# TMS320F280049 register map
Vendor: Texas Instruments; Series: C2000 F28004x; File version: 0.2.0-generated
Registers are 16-bit, read-write, reset 0x0 unless marked. A register's access mark holds for its fields unless they carry their own. Offsets are from the block's base; [hi:lo] are bit positions; {n}, {i} and the like mark numbered series; 'fields as' and 'values as' point back to an identical list.

## GPIOCTRLREGS — GPIO CTRL Registers
Base 0x0000F800
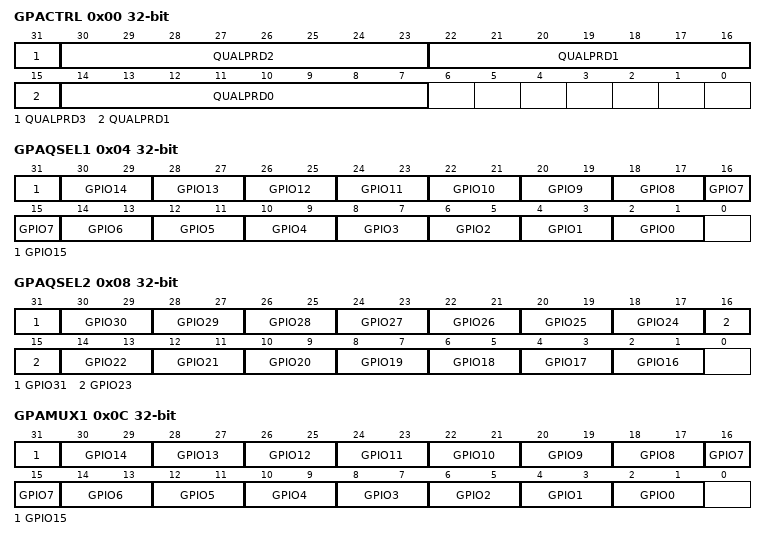
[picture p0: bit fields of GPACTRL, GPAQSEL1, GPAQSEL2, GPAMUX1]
0x00 GPACTRL 32-bit — GPIO A Qualification Sampling Period (GPIO0 to GPIO31)
  [31] QUALPRD3 — Qualification sampling period for GPIO24 to GPIO31
  [30:23] QUALPRD2 — Qualification sampling period for GPIO16 to GPIO23
  [22:15] QUALPRD1 — Qualification sampling period for GPIO8 to GPIO15
  [14:7] QUALPRD0 — Qualification sampling period for GPIO0 to GPIO7
0x04 GPAQSEL1 32-bit — GPIO A Qualification Type (GPIO0 to GPIO15)
  [31] GPIO15 — Select input qualification type for GPIO15
  [2n+2:2n+1] GPIO{n} (n=0..14) — Select input qualification type for GPIO{n}
0x08 GPAQSEL2 32-bit — GPIO A Qualification Type (GPIO16 to GPIO31)
  [31] GPIO31 — Select input qualification type for GPIO31
  [2n-30:2n-31] GPIO{n} (n=16..30) — Select input qualification type for GPIO{n}
0x0C GPAMUX1 32-bit — GPIO A Peripheral Mux (GPIO0 to GPIO15)
  [31] GPIO15 — Defines pin-muxing selection for GPIO15
  [2n+2:2n+1] GPIO{n} (n=0..14) — Defines pin-muxing selection for GPIO{n}
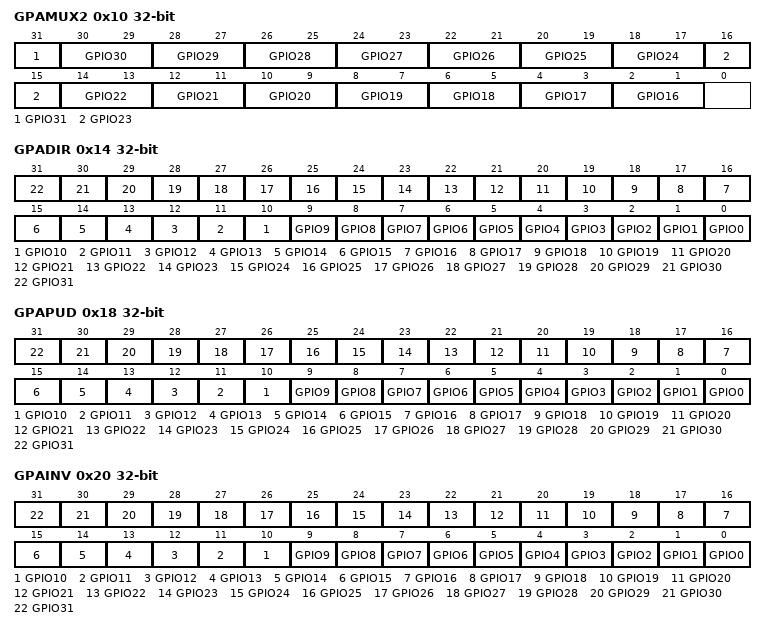
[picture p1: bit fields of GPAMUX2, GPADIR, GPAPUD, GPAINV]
0x10 GPAMUX2 32-bit — GPIO A Peripheral Mux (GPIO16 to GPIO31)
  [31] GPIO31 — Defines pin-muxing selection for GPIO31
  [2n-30:2n-31] GPIO{n} (n=16..30) — Defines pin-muxing selection for GPIO{n}
0x14 GPADIR 32-bit — GPIO A Direction (GPIO0 to GPIO31)
  [n] GPIO{n} (n=0..31) — Defines direction for this pin in GPIO mode
0x18 GPAPUD 32-bit — GPIO A Pull-Up Disable (GPIO0 to GPIO31)
  [n] GPIO{n} (n=0..31) — Pull-Up Disable control for this pin
0x20 GPAINV 32-bit — GPIO A Input Inversion (GPIO0 to GPIO31)
  [n] GPIO{n} (n=0..31) — Input inversion control for this pin
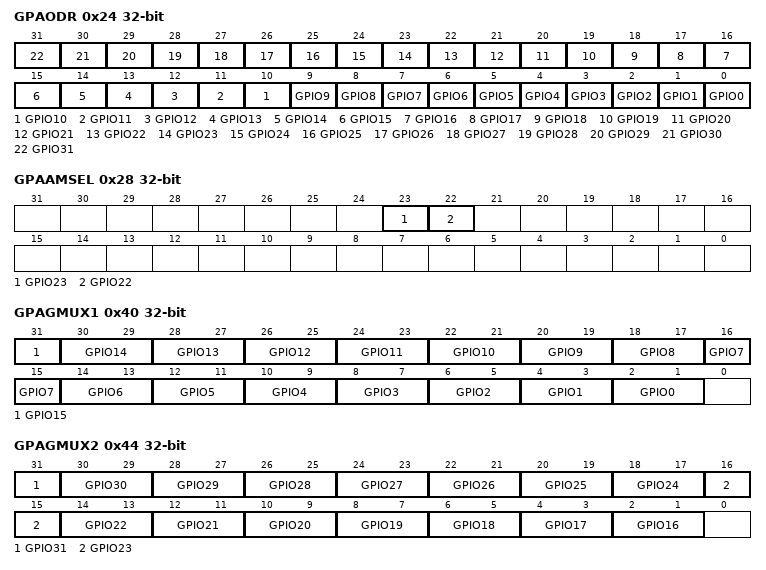
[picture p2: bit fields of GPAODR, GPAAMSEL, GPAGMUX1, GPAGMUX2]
0x24 GPAODR 32-bit — GPIO A Open Drain Output Mode (GPIO0 to GPIO31)
  [n] GPIO{n} (n=0..31) — Output Open-Drain control for this pin
0x28 GPAAMSEL 32-bit — GPIO A Analog Mode Select (GPIO0 to GPIO31)
  [23] GPIO23 — Analog Mode select for this pin
  [22] GPIO22 — Analog Mode select for this pin
0x40 GPAGMUX1 32-bit — GPIO A Peripheral Group Mux (GPIO0 to GPIO15)
  fields as GPAMUX1
0x44 GPAGMUX2 32-bit — GPIO A Peripheral Group Mux (GPIO16 to GPIO31)
  fields as GPAMUX2
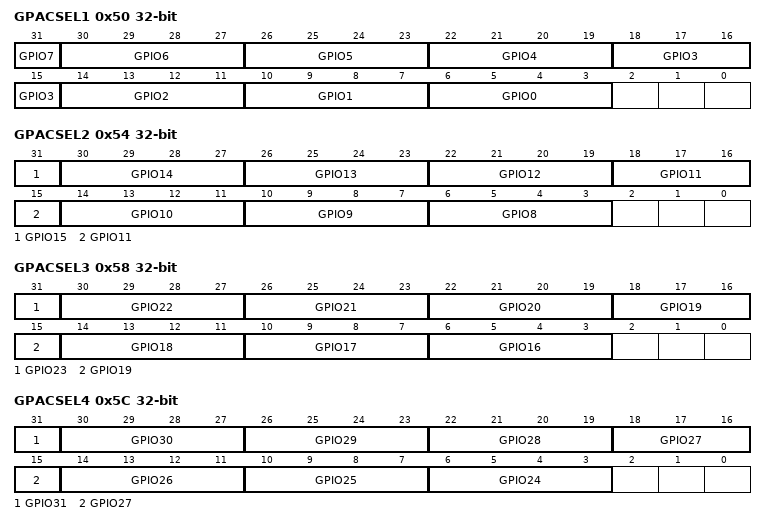
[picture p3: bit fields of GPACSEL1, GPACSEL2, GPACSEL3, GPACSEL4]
0x50 GPACSEL1 32-bit — GPIO A Master Core Select (GPIO0 to GPIO7)
  [31] GPIO7 — GPIO7 Master CPU Select
  [4n+6:4n+3] GPIO{n} (n=0..6) — GPIO{n} Master CPU Select
0x54 GPACSEL2 32-bit — GPIO A Master Core Select (GPIO8 to GPIO15)
  [31] GPIO15 — GPIO15 Master CPU Select
  [4n-26:4n-29] GPIO{n} (n=8..14) — GPIO{n} Master CPU Select
0x58 GPACSEL3 32-bit — GPIO A Master Core Select (GPIO16 to GPIO23)
  [31] GPIO23 — GPIO23 Master CPU Select
  [4n-58:4n-61] GPIO{n} (n=16..22) — GPIO{n} Master CPU Select
0x5C GPACSEL4 32-bit — GPIO A Master Core Select (GPIO24 to GPIO31)
  [31] GPIO31 — GPIO31 Master CPU Select
  [4n-90:4n-93] GPIO{n} (n=24..30) — GPIO{n} Master CPU Select
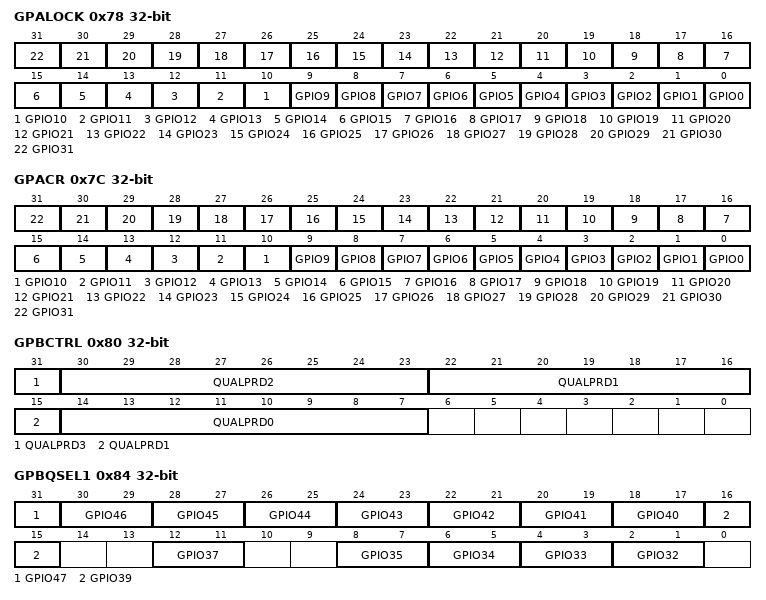
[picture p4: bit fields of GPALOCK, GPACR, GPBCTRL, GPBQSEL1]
0x78 GPALOCK 32-bit — GPIO A Lock Register (GPIO0 to GPIO31)
  [n] GPIO{n} (n=0..31) — Configuration Lock bit for this pin
0x7C GPACR 32-bit — GPIO A Lock Commit Register (GPIO0 to GPIO31)
  [n] GPIO{n} (n=0..31) — Configuration lock commit bit for this pin
0x80 GPBCTRL 32-bit — GPIO B Qualification Sampling Period (GPIO32 to GPIO63)
  [31] QUALPRD3 — Qualification sampling period for GPIO56 to GPIO63
  [30:23] QUALPRD2 — Qualification sampling period for GPIO48 to GPIO55
  [22:15] QUALPRD1 — Qualification sampling period for GPIO40 to GPIO47
  [14:7] QUALPRD0 — Qualification sampling period for GPIO32 to GPIO39
0x84 GPBQSEL1 32-bit — GPIO B Qualification Type (GPIO32 to GPIO47)
  [31] GPIO47 — Select input qualification type for GPIO47
  [2n-62:2n-63] GPIO{n} (n=39..46) — Select input qualification type for GPIO{n}
  [12:11] GPIO37 — Select input qualification type for GPIO37
  [2n-62:2n-63] GPIO{n} (n=32..35) — Select input qualification type for GPIO{n}
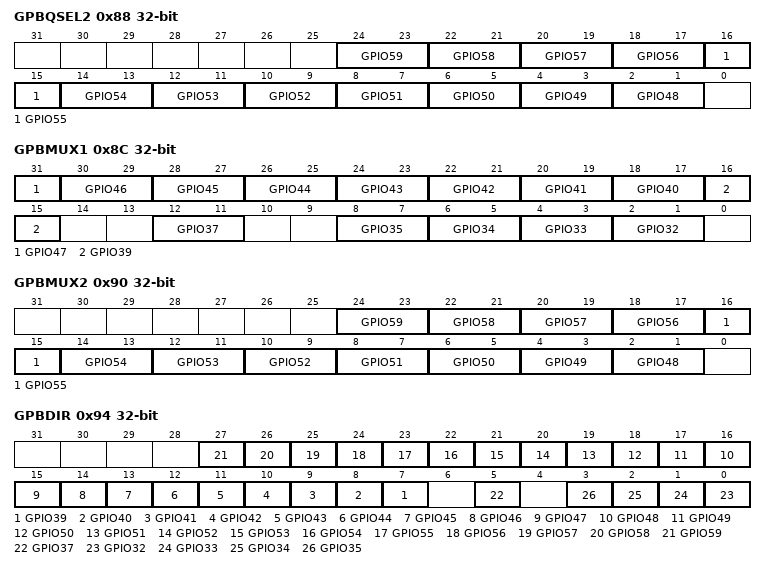
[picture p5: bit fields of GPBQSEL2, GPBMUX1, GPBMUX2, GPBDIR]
0x88 GPBQSEL2 32-bit — GPIO B Qualification Type (GPIO48 to GPIO63)
  [2n-94:2n-95] GPIO{n} (n=48..59) — Select input qualification type for GPIO{n}
0x8C GPBMUX1 32-bit — GPIO B Peripheral Mux (GPIO32 to GPIO47)
  [31] GPIO47 — Defines pin-muxing selection for GPIO47
  [2n-62:2n-63] GPIO{n} (n=39..46) — Defines pin-muxing selection for GPIO{n}
  [12:11] GPIO37 — Defines pin-muxing selection for GPIO37
  [2n-62:2n-63] GPIO{n} (n=32..35) — Defines pin-muxing selection for GPIO{n}
0x90 GPBMUX2 32-bit — GPIO B Peripheral Mux (GPIO48 to GPIO63)
  [2n-94:2n-95] GPIO{n} (n=48..59) — Defines pin-muxing selection for GPIO{n}
0x94 GPBDIR 32-bit — GPIO B Direction (GPIO32 to GPIO63)
  [n-32] GPIO{n} (n=39..59) — Defines direction for this pin in GPIO mode
  [5] GPIO37 — Defines direction for this pin in GPIO mode
  [n-32] GPIO{n} (n=32..35) — Defines direction for this pin in GPIO mode
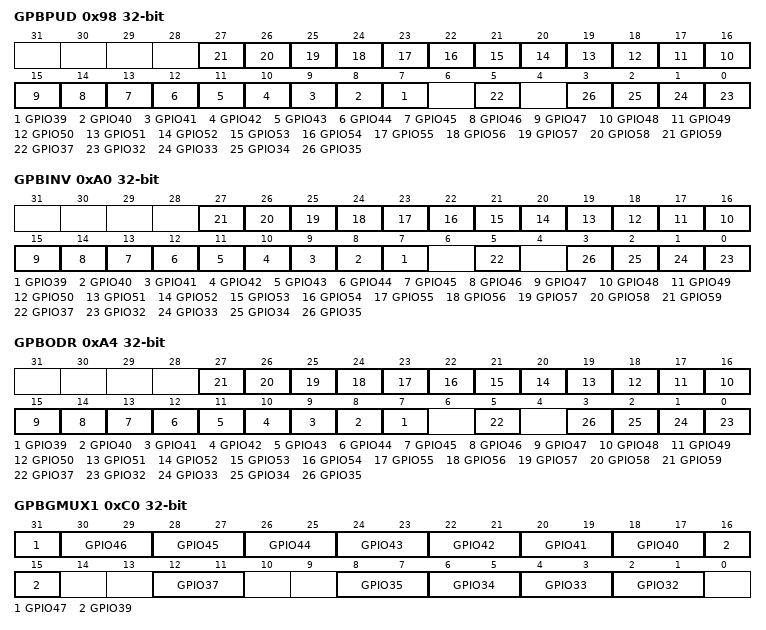
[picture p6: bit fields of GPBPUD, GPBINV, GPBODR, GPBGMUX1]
0x98 GPBPUD 32-bit — GPIO B Pull-Up Disable (GPIO32 to GPIO63)
  [n-32] GPIO{n} (n=39..59) — Pull-Up Disable control for this pin
  [5] GPIO37 — Pull-Up Disable control for this pin
  [n-32] GPIO{n} (n=32..35) — Pull-Up Disable control for this pin
0xA0 GPBINV 32-bit — GPIO B Input Inversion (GPIO32 to GPIO63)
  [n-32] GPIO{n} (n=39..59) — Input inversion control for this pin
  [5] GPIO37 — Input inversion control for this pin
  [n-32] GPIO{n} (n=32..35) — Input inversion control for this pin
0xA4 GPBODR 32-bit — GPIO B Open Drain Output Mode (GPIO32 to GPIO63)
  [n-32] GPIO{n} (n=39..59) — Output Open-Drain control for this pin
  [5] GPIO37 — Output Open-Drain control for this pin
  [n-32] GPIO{n} (n=32..35) — Output Open-Drain control for this pin
0xC0 GPBGMUX1 32-bit — GPIO B Peripheral Group Mux (GPIO32 to GPIO47)
  fields as GPBMUX1
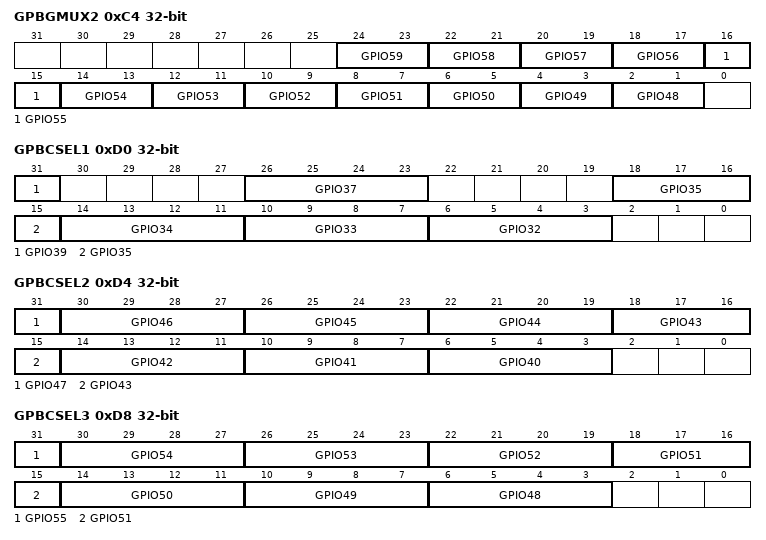
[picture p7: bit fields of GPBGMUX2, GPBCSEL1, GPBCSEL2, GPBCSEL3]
0xC4 GPBGMUX2 32-bit — GPIO B Peripheral Group Mux (GPIO48 to GPIO63)
  fields as GPBMUX2
0xD0 GPBCSEL1 32-bit — GPIO B Master Core Select (GPIO32 to GPIO39)
  [31] GPIO39 — GPIO39 Master CPU Select
  [26:23] GPIO37 — GPIO37 Master CPU Select
  [4n-122:4n-125] GPIO{n} (n=32..35) — GPIO{n} Master CPU Select
0xD4 GPBCSEL2 32-bit — GPIO B Master Core Select (GPIO40 to GPIO47)
  [31] GPIO47 — GPIO47 Master CPU Select
  [4n-154:4n-157] GPIO{n} (n=40..46) — GPIO{n} Master CPU Select
0xD8 GPBCSEL3 32-bit — GPIO B Master Core Select (GPIO48 to GPIO55)
  [31] GPIO55 — GPIO55 Master CPU Select
  [4n-186:4n-189] GPIO{n} (n=48..54) — GPIO{n} Master CPU Select
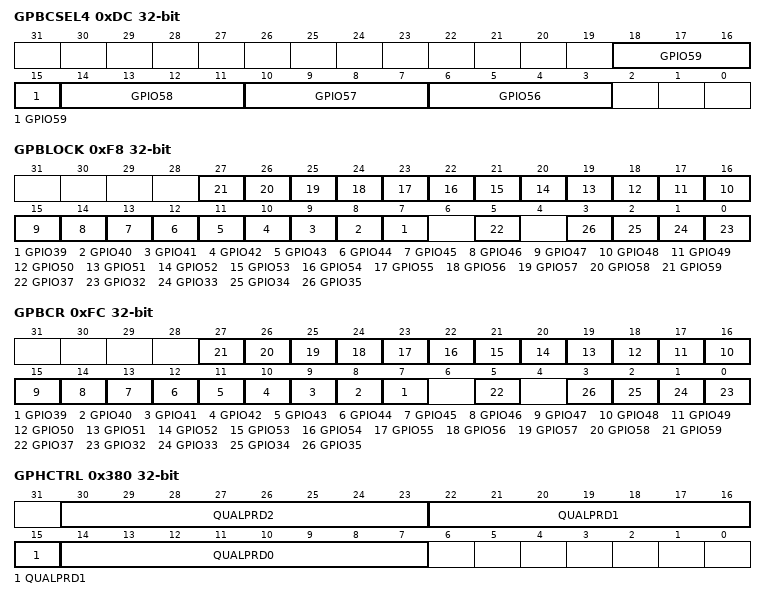
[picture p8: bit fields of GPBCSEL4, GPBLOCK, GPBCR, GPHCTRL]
0xDC GPBCSEL4 32-bit — GPIO B Master Core Select (GPIO56 to GPIO63)
  [4n-218:4n-221] GPIO{n} (n=56..59) — GPIO{n} Master CPU Select
0xF8 GPBLOCK 32-bit — GPIO B Lock Register (GPIO32 to GPIO63)
  [n-32] GPIO{n} (n=39..59) — Configuration Lock bit for this pin
  [5] GPIO37 — Configuration Lock bit for this pin
  [n-32] GPIO{n} (n=32..35) — Configuration Lock bit for this pin
0xFC GPBCR 32-bit — GPIO B Lock Commit Register (GPIO32 to GPIO63)
  [n-32] GPIO{n} (n=39..59) — Configuration lock commit bit for this pin
  [5] GPIO37 — Configuration lock commit bit for this pin
  [n-32] GPIO{n} (n=32..35) — Configuration lock commit bit for this pin
0x380 GPHCTRL 32-bit — GPIO H Qualification Sampling Period (GPIO224 to GPIO255)
  [30:23] QUALPRD2 — Qualification sampling period for GPIO240 to GPIO247
  [22:15] QUALPRD1 — Qualification sampling period for GPIO232 to GPIO239
  [14:7] QUALPRD0 — Qualification sampling period for GPIO224 to GPIO231
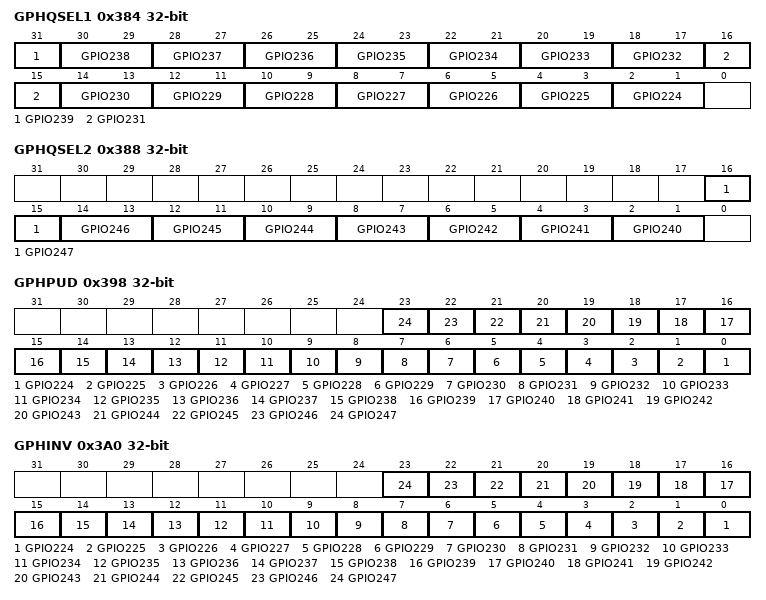
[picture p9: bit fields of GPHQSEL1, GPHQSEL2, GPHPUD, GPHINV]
0x384 GPHQSEL1 32-bit — GPIO H Qualification Type (GPIO224 to GPIO239)
  [31] GPIO239 — Select input qualification type for this GPIO Pin
  [2n-446:2n-447] GPIO{n} (n=224..238) — Select input qualification type for this GPIO Pin
0x388 GPHQSEL2 32-bit — GPIO H Qualification Type (GPIO240 to GPIO255)
  [2n-478:2n-479] GPIO{n} (n=240..247) — Select input qualification type for this GPIO Pin
0x398 GPHPUD 32-bit — GPIO H Pull-Up Disable (GPIO224 to GPIO255)
  [n-224] GPIO{n} (n=224..247) — Pull-Up Disable control for this pin
0x3A0 GPHINV 32-bit — GPIO H Input Inversion (GPIO224 to GPIO255)
  [n-224] GPIO{n} (n=224..247) — Input inversion control for this pin
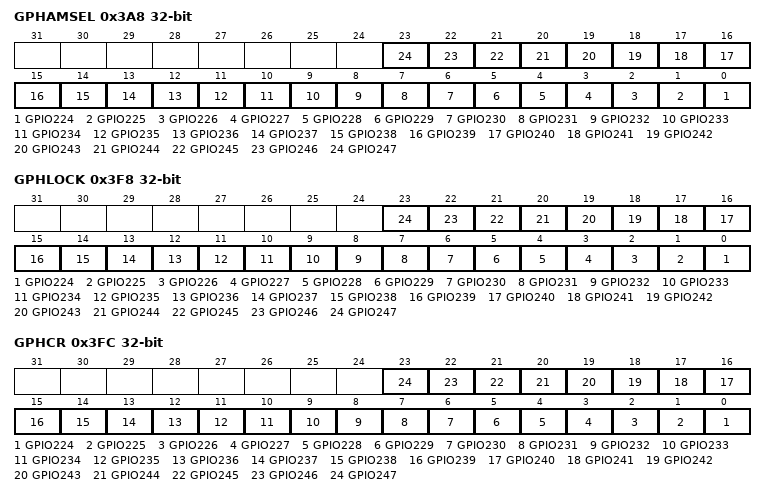
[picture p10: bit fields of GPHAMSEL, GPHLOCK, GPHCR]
0x3A8 GPHAMSEL 32-bit — GPIO H Analog Mode Select (GPIO224 to GPIO255)
  [n-224] GPIO{n} (n=224..247) — Analog Mode select for this pin
0x3F8 GPHLOCK 32-bit — GPIO H Lock Register (GPIO224 to GPIO255)
  [n-224] GPIO{n} (n=224..247) — Configuration Lock bit for this pin
0x3FC GPHCR 32-bit — GPIO H Lock Commit Register (GPIO224 to GPIO255)
  [n-224] GPIO{n} (n=224..247) — Configuration lock commit bit for this pin
